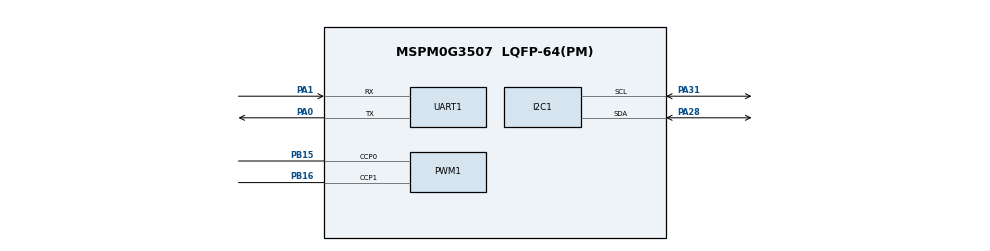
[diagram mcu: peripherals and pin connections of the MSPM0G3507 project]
//@cliArgs --device "MSPM0G350X" --package "LQFP-64(PM)" --part "Default"
//@v2CliArgs --device "MSPM0G3507" --package "LQFP-64(PM)"
// @cliArgs --board /ti/boards/LP_MSPM0G3507 --rtos nortos

/**
 * Import the modules used in this configuration.
 */
const SYSCTL = scripting.addModule("/ti/driverlib/SYSCTL");
const UART   = scripting.addModule("/ti/driverlib/UART", {}, false);
const UART1  = UART.addInstance();
const I2C    = scripting.addModule("/ti/driverlib/I2C", {}, false);
const I2C1   = I2C.addInstance();
const PWM    = scripting.addModule("/ti/driverlib/PWM", {}, false);
const PWM1   = PWM.addInstance();

/**
 * Write custom configuration values to the imported modules.
 */

const Board = scripting.addModule("/ti/driverlib/Board", {}, false);

SYSCTL.forceDefaultClkConfig = true;

UART1.$name                    = "UART_0";
UART1.targetBaudRate           = 115200;
UART1.enableFIFO               = true;
UART1.rxFifoThreshold          = "DL_UART_RX_FIFO_LEVEL_ONE_ENTRY";
UART1.txFifoThreshold          = "DL_UART_TX_FIFO_LEVEL_3_4_EMPTY";
UART1.peripheral.$assign       = "UART0";
UART1.peripheral.txPin.$assign = "PA0";
UART1.peripheral.rxPin.$assign = "PA1";
UART1.txPinConfig.$name        = "GPIO_UART0_TX";
UART1.rxPinConfig.$name        = "GPIO_UART0_RX";

I2C1.$name                     = "I2C_OLED";
I2C1.basicEnableController     = true;
I2C1.basicControllerBusSpeed   = 400000;
I2C1.advControllerTXFIFOTRIG   = "BYTES_1";
I2C1.peripheral.$assign        = "I2C0";
I2C1.peripheral.sdaPin.$assign = "PA28";
I2C1.peripheral.sclPin.$assign = "PA31";
I2C1.sdaPinConfig.$name        = "GPIO_I2C0_SDA";
I2C1.sclPinConfig.$name        = "GPIO_I2C0_SCL";

PWM1.$name                      = "MOTOR_PWM";
PWM1.clockPrescale              = 1;
PWM1.timerCount                 = 2133;
PWM1.peripheral.$assign         = "TIMG8";
PWM1.peripheral.ccp0Pin.$assign = "PB15";
PWM1.peripheral.ccp1Pin.$assign = "PB16";
PWM1.PWM_CHANNEL_0.$name        = "PWM_MOTOR_RIGHT";
PWM1.PWM_CHANNEL_0.dutyCycle    = 0;
PWM1.PWM_CHANNEL_0.ccValue      = 2133;
PWM1.PWM_CHANNEL_1.$name        = "PWM_MOTOR_LEFT";
PWM1.PWM_CHANNEL_1.dutyCycle    = 0;
PWM1.PWM_CHANNEL_1.ccValue      = 2133;
